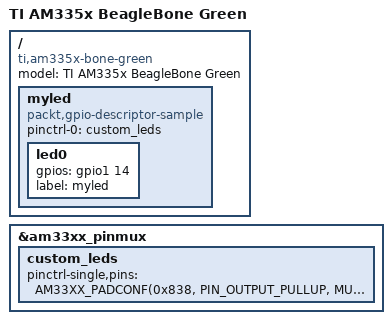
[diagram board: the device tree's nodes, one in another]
// SPDX-License-Identifier: GPL-2.0-only
/*
 * Copyright (C) 2012 Texas Instruments Incorporated - https://www.ti.com/
 */
/dts-v1/;

#include "am33xx.dtsi"
#include "am335x-bone-common.dtsi"
#include "am335x-bonegreen-common.dtsi"

&am33xx_pinmux {
	custom_leds: custom_leds {
		pinctrl-single,pins = <
			AM33XX_PADCONF(0x838, PIN_OUTPUT_PULLUP, MUX_MODE7)	/* gpmc_ad14.gpio1_14 */
		>;
	};
};

/ {
	model = "TI AM335x BeagleBone Green";
	compatible = "ti,am335x-bone-green", "ti,am335x-bone-black", "ti,am335x-bone", "ti,am33xx";

	myled {
        compatible = "packt,gpio-descriptor-sample";
        pinctrl-names = "default";
        pinctrl-0 = <&custom_leds>;
		
		led0 {
			gpios = <&gpio1 14 GPIO_ACTIVE_HIGH>;
			label = "myled";
		};
	};
};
